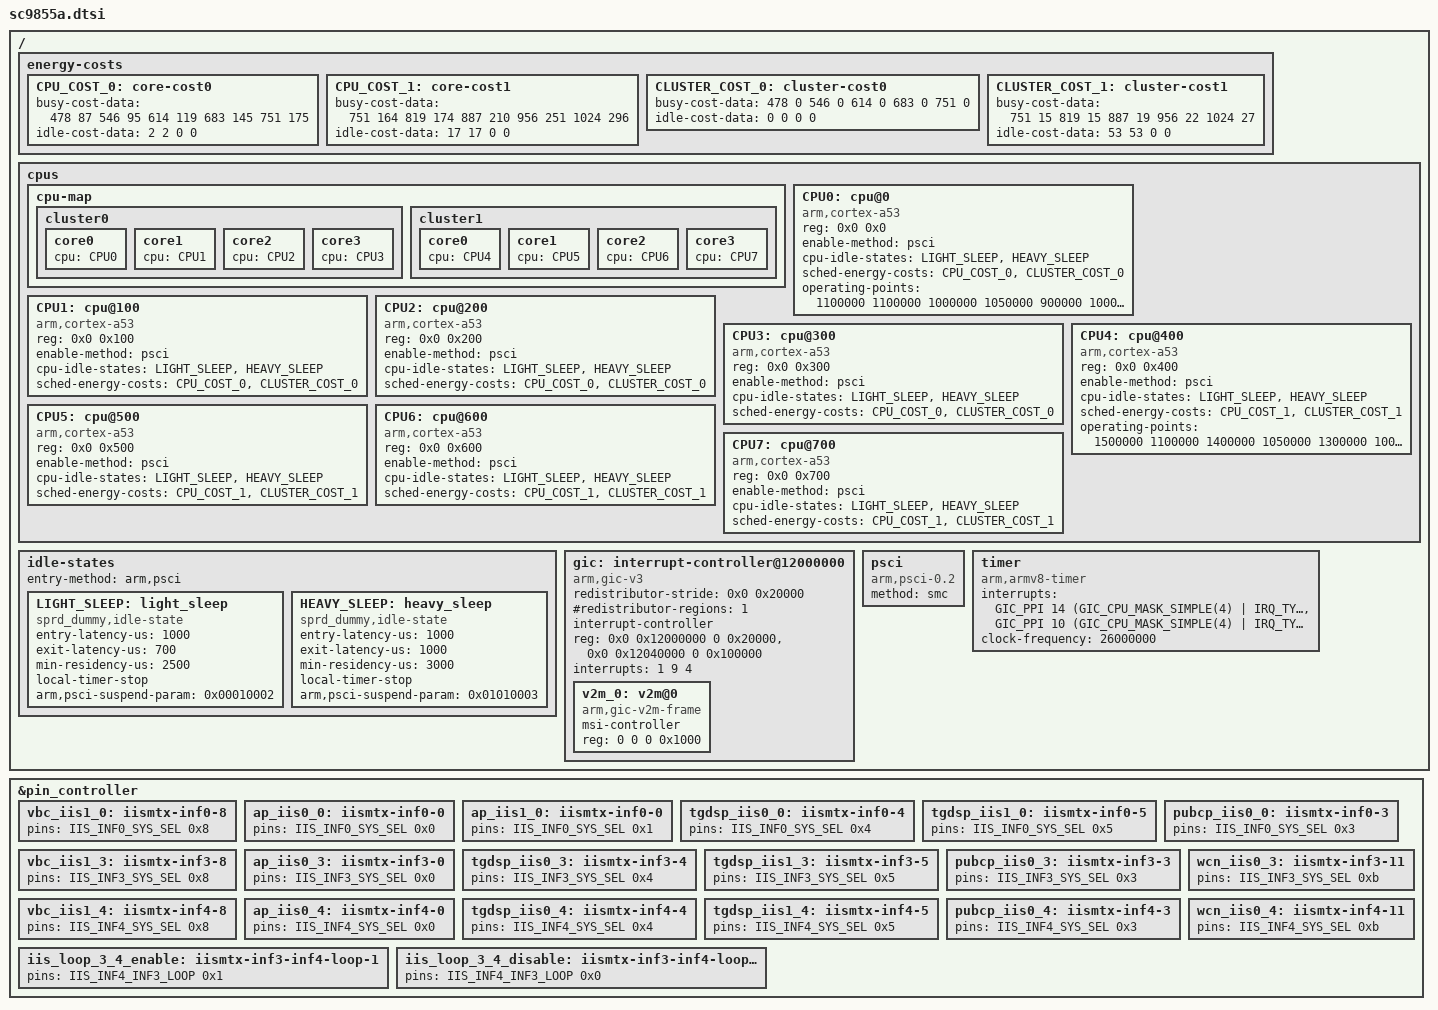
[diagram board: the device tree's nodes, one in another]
/*
 * Spreadtrum SC9855A SoC DTS file
 *
 * Copyright (C) 2017, Spreadtrum Communications Inc.
 *
 * This file is licensed under a dual GPLv2 or X11 license.
 */

#include "sharkl3.dtsi"
#include "sc9855a-clocks.dtsi"
#include <dt-bindings/pinctrl/sc9863_pinctrl.h>

/ {
	energy-costs {
		CPU_COST_0: core-cost0 {
			busy-cost-data = <
				478	87	/* 700MHz */
				546	95	/* 800MHz */
				614	119	/* 900MHz */
				683	145	/* 1000MHz */
				751	175	/* 1100MHz */
			>;
			idle-cost-data = <
				2		/* ACTIVE-IDLE */
				2		/* WFI */
				0		/* LIGHT_SLEEP */
				0		/* HEAVY_SLEEP */
			>;
		};
		CPU_COST_1: core-cost1 {
			busy-cost-data = <
				751	164
				819	174
				887	210
				956	251
				1024	296
			>;
			idle-cost-data = <
				17		/* ACTIVE-IDLE */
				17
				0
				0
			>;
		};
		CLUSTER_COST_0: cluster-cost0 {
			busy-cost-data = <
				478	0	/* 700MHz */
				546	0
				614	0
				683	0
				751	0
			>;
			idle-cost-data = <
				0		/* ACTIVE-IDLE */
				0
				0
				0
			>;
		};
		CLUSTER_COST_1: cluster-cost1 {
			busy-cost-data = <
				751	15
				819	15
				887	19
				956	22
			       1024	27
			>;
			idle-cost-data = <
				53		/* ACTIVE-IDLE */
				53
				0
				0
			>;
		};
	};

	cpus {
		#address-cells = <2>;
		#size-cells = <0>;

		cpu-map {
			cluster0 {
				core0 {
					cpu = <&CPU0>;
				};
				core1 {
					cpu = <&CPU1>;
				};
				core2 {
					cpu = <&CPU2>;
				};
				core3 {
					cpu = <&CPU3>;
				};
			};
			cluster1 {
				core0 {
					cpu = <&CPU4>;
				};
				core1 {
					cpu = <&CPU5>;
				};
				core2 {
					cpu = <&CPU6>;
				};
				core3 {
					cpu = <&CPU7>;
				};
			};
		};

		CPU0: cpu@0 {
			device_type = "cpu";
			compatible = "arm,cortex-a53","arm,armv8";
			reg = <0x0 0x0>;
			enable-method = "psci";
			cpu-idle-states = <&LIGHT_SLEEP &HEAVY_SLEEP>;
			sched-energy-costs = <&CPU_COST_0 &CLUSTER_COST_0>;
			operating-points = <
				1100000	1100000
				1000000	1050000
				900000	1000000
				800000	950000
				700000	900000
			>;
		};
		CPU1: cpu@100 {
			device_type = "cpu";
			compatible = "arm,cortex-a53","arm,armv8";
			reg = <0x0 0x100>;
			enable-method = "psci";
			cpu-idle-states = <&LIGHT_SLEEP &HEAVY_SLEEP>;
			sched-energy-costs = <&CPU_COST_0 &CLUSTER_COST_0>;
		};
		CPU2: cpu@200 {
			device_type = "cpu";
			compatible = "arm,cortex-a53","arm,armv8";
			reg = <0x0 0x200>;
			enable-method = "psci";
			cpu-idle-states = <&LIGHT_SLEEP &HEAVY_SLEEP>;
			sched-energy-costs = <&CPU_COST_0 &CLUSTER_COST_0>;
		};
		CPU3: cpu@300 {
			device_type = "cpu";
			compatible = "arm,cortex-a53","arm,armv8";
			reg = <0x0 0x300>;
			enable-method = "psci";
			cpu-idle-states = <&LIGHT_SLEEP &HEAVY_SLEEP>;
			sched-energy-costs = <&CPU_COST_0 &CLUSTER_COST_0>;
		};
		CPU4: cpu@400 {
			device_type = "cpu";
			compatible = "arm,cortex-a53","arm,armv8";
			reg = <0x0 0x400>;
			enable-method = "psci";
			cpu-idle-states = <&LIGHT_SLEEP &HEAVY_SLEEP>;
			sched-energy-costs = <&CPU_COST_1 &CLUSTER_COST_1>;
			operating-points = <
				1500000 1100000
				1400000 1050000
				1300000 1000000
				1200000	950000
				1100000 900000>;
		};
		CPU5: cpu@500 {
			device_type = "cpu";
			compatible = "arm,cortex-a53","arm,armv8";
			reg = <0x0 0x500>;
			enable-method = "psci";
			cpu-idle-states = <&LIGHT_SLEEP &HEAVY_SLEEP>;
			sched-energy-costs = <&CPU_COST_1 &CLUSTER_COST_1>;
		};
		CPU6: cpu@600 {
			device_type = "cpu";
			compatible = "arm,cortex-a53","arm,armv8";
			reg = <0x0 0x600>;
			enable-method = "psci";
			cpu-idle-states = <&LIGHT_SLEEP &HEAVY_SLEEP>;
			sched-energy-costs = <&CPU_COST_1 &CLUSTER_COST_1>;
		};
		CPU7: cpu@700 {
			device_type = "cpu";
			compatible = "arm,cortex-a53","arm,armv8";
			reg = <0x0 0x700>;
			enable-method = "psci";
			cpu-idle-states = <&LIGHT_SLEEP &HEAVY_SLEEP>;
			sched-energy-costs = <&CPU_COST_1 &CLUSTER_COST_1>;
		};

	};

	idle-states {
		entry-method = "arm,psci";
		LIGHT_SLEEP: light_sleep {
			compatible = "sprd_dummy,idle-state";
			entry-latency-us = <1000>;
			exit-latency-us = <700>;
			min-residency-us = <2500>;
			local-timer-stop;
			arm,psci-suspend-param = <0x00010002>;
		};
		HEAVY_SLEEP: heavy_sleep {
			compatible = "sprd_dummy,idle-state";
			entry-latency-us = <1000>;
			exit-latency-us = <1000>;
			min-residency-us = <3000>;
			local-timer-stop;
			arm,psci-suspend-param = <0x01010003>;
		};
	};

	gic: interrupt-controller@12000000 {
		compatible = "arm,gic-v3";
		#interrupt-cells = <3>;
		#address-cells = <2>;
		#size-cells = <2>;
		ranges;
		redistributor-stride = <0x0 0x20000>;	// 128KB stride
		#redistributor-regions = <1>;
		interrupt-controller;
		reg = <0x0 0x12000000 0 0x20000>,	// GICD
			<0x0 0x12040000 0 0x100000>;	// GICR
		interrupts = <1 9 4>;
		v2m_0: v2m@0 {
			compatible = "arm,gic-v2m-frame";
			msi-controller;
			reg = <0 0 0 0x1000>;
		};
	};

	psci {
		compatible = "arm,psci-0.2";
		method = "smc";
	};

	timer {
		compatible = "arm,armv8-timer";
		interrupts = <GIC_PPI 14 (GIC_CPU_MASK_SIMPLE(4)
					 | IRQ_TYPE_LEVEL_LOW)>,
			     <GIC_PPI 10 (GIC_CPU_MASK_SIMPLE(4)
					 | IRQ_TYPE_LEVEL_LOW)>;
		clock-frequency = <26000000>;
	};
};

&pin_controller {
	vbc_iis1_0: iismtx-inf0-8 {
		pins = <IIS_INF0_SYS_SEL 0x8>;
	};
	ap_iis0_0: iismtx-inf0-0 {
		pins = <IIS_INF0_SYS_SEL 0x0>;
	};
	ap_iis1_0: iismtx-inf0-0 {
		pins = <IIS_INF0_SYS_SEL 0x1>;
	};
	tgdsp_iis0_0: iismtx-inf0-4 {
		pins = <IIS_INF0_SYS_SEL 0x4>;
	};
	tgdsp_iis1_0: iismtx-inf0-5 {
		pins = <IIS_INF0_SYS_SEL 0x5>;
	};
	pubcp_iis0_0: iismtx-inf0-3 {
		pins = <IIS_INF0_SYS_SEL 0x3>;
	};
	vbc_iis1_3: iismtx-inf3-8 {
		pins = <IIS_INF3_SYS_SEL 0x8>;
	};
	ap_iis0_3: iismtx-inf3-0 {
		pins = <IIS_INF3_SYS_SEL 0x0>;
	};
	tgdsp_iis0_3: iismtx-inf3-4 {
		pins = <IIS_INF3_SYS_SEL 0x4>;
	};
	tgdsp_iis1_3: iismtx-inf3-5 {
		pins = <IIS_INF3_SYS_SEL 0x5>;
	};
	pubcp_iis0_3: iismtx-inf3-3 {
		pins = <IIS_INF3_SYS_SEL 0x3>;
	};
	wcn_iis0_3: iismtx-inf3-11 {
		pins = <IIS_INF3_SYS_SEL 0xb>;
	};
	vbc_iis1_4: iismtx-inf4-8 {
		pins = <IIS_INF4_SYS_SEL 0x8>;
	};
	ap_iis0_4: iismtx-inf4-0 {
		pins = <IIS_INF4_SYS_SEL 0x0>;
	};
	tgdsp_iis0_4: iismtx-inf4-4 {
		pins = <IIS_INF4_SYS_SEL 0x4>;
	};
	tgdsp_iis1_4: iismtx-inf4-5 {
		pins = <IIS_INF4_SYS_SEL 0x5>;
	};
	pubcp_iis0_4: iismtx-inf4-3 {
		pins = <IIS_INF4_SYS_SEL 0x3>;
	};
	wcn_iis0_4: iismtx-inf4-11 {
		pins = <IIS_INF4_SYS_SEL 0xb>;
	};
	iis_loop_3_4_enable: iismtx-inf3-inf4-loop-1 {
		pins = <IIS_INF4_INF3_LOOP 0x1>;
	};
	iis_loop_3_4_disable: iismtx-inf3-inf4-loop-0 {
		pins = <IIS_INF4_INF3_LOOP 0x0>;
	};
};
